# MDR32F02_rev1 register map
File version: 2.0
MDR32F02. Rev. 1.x
CPU: BM-310S, little endian
Registers are 32-bit, read-write, no defined reset value unless marked. A register's access mark holds for its fields unless they carry their own. Offsets are from the block's base; lines under a group give offsets from that group; [hi:lo] are bit positions; {n}, {i} and the like mark numbered series; 'fields as' and 'values as' point back to an identical list; <NAME> marks a mode.

## Memory map
0x02000000 CLINT blocks up to offset 0xC000 — Core Local Interrupt Controller
0x0C000000 PLIC blocks up to offset 0x200008 — Platform Level Interrupt Controller
0x40000000 SSP1 size 0x1000 — SSP1 Interface
0x40008000 UART1 size 0x1000 — UART1 Controller
0x40010000 UART2 size 0x1000 — UART2 Controller
0x40018000 FLASH_CNTRL size 0x1000 — FLASH Memory Controller
0x40020000 RST_CLK size 0x1000 — RST_CLK description
0x40028000 DMA size 0x1000 — DMA description
0x40030000 I2C size 0x1000 — I2C description
0x40038000 UART3 size 0x1000 — UART3 Controller
0x40040000 ADC size 0x1000 — ADC description
0x40048000 WWDG size 0x1000 — WWDG description
0x40050000 IWDG size 0x1000 — IWDG description
0x40058000 POWER size 0x1000 — POWER description
0x40060000 BKP size 0x1000 — BKP description
0x40068000 ADCUI size 0x1000 — ADCUI description
0x40070000 TIMER1 size 0x1000 — TIMER1 description
0x40078000 TIMER2 size 0x1000 — TIMER2 description
0x40080000 PORTA size 0x1000 — PORTA description
0x40088000 PORTB size 0x1000 — PORTB description
0x40090000 PORTC size 0x1000 — PORTC description
0x40098000 CRC size 0x1000 — CRC description
0x400A8000 SENSORS size 0x1000 — SENSORS description
0x400B0000 CLK_MEASURE size 0x1000 — CLK_MEASURE description
0x400B8000 RANDOM size 0x1000 — RANDOM description
0x400C0000 USART size 0x1000 — USART description
0x400C8000 SSP2 size 0x1000 — SSP2 Interface
0x400D0000 SSP3 size 0x1000 — SSP3 Interface
0x400D8000 TIMER3 size 0x1000 — TIMER3 description
0x400E0000 TIMER4 size 0x1000 — TIMER4 description
0x400E8000 UART4 size 0x1000 — UART4 Controller
0x400F0000 PORTD size 0x1000 — PORTD description
0x60004000 L_BLOCK size 0x1000 — L_BLOCK description
{0x60008000+0x4000*n} S_BLOCK{n} size 0x1000 (n=0..7) — S_BLOCK{n} description
0x60028000 P_BYTE size 0x1000 — P_BYTE description
0x6002C000 P_BIT0 size 0x1000 — P_BIT0 description
0x60030000 P_BIT1 size 0x1000 — P_BIT1 description
0x60034000 P_BIT2 size 0x1000 — P_BIT2 description
0x60038000 P_BIT3 size 0x1000 — P_BIT3 description
0x70010000 OTP size 0x1000 — OTP description

## Interrupts
0 DMA_IRQ (DMA)
1 UART1_IRQ (UART1)
2 UART2_IRQ (UART2)
3 SSP1_IRQ (SSP1)
4 POWER_IRQ (POWER)
5 WWDG_IRQ (WWDG)
6 TIMER1_IRQ (TIMER1)
7 TIMER2_IRQ (TIMER2)
8 ADC_IRQ (ADC)
9 I2C_IRQ (I2C)
10 BKP_IRQ (BKP)
11 EXT_INT1_IRQ (PORTA)
12 EXT_INT2_IRQ (PORTB)
13 EXT_INT3_IRQ (PORTC)
14 ADCUI_F03_IRQn (ADCUI)
15 ADCUI_F1_IRQn (ADCUI)
16 ADCUI_F2_IRQn (ADCUI)
17 L_BLOCK_IRQ (L_BLOCK)
19 SENSORS_IRQ (SENSORS)
20 CLK_MEASURE_IRQ (CLK_MEASURE)
21 RANDOM_IRQ (RANDOM)
22 USART_IRQ (USART)
23 UART3_IRQ (UART3)
24 SSP2_IRQ (SSP2)
25 SSP3_IRQ (SSP3)
26 TIMER3_IRQ (TIMER3)
27 TIMER4_IRQ (TIMER4)
28 UART4_IRQ (UART4)
29 OTP_IRQ (OTP)

## CLINT — Core Local Interrupt Controller
Base 0x02000000
0x00 CTMSIP — Software Interrupt Request/Clear Register
0x4000 CTMTIMECMP 64-bit — Machine Timer Compare Register
0xBFF8 CTMTIME 64-bit — Machine Timer Value Register

## PLIC — Platform Level Interrupt Controller
Base 0x0C000000
0x04 PRI1 — 1st Interrupt Priority Register
  [2:0] PRI — Interrupt Priority
0x08 PRI2 — 2nd Interrupt Priority Register
  [2:0] PRI — Interrupt Priority
0x0C PRI3 — 3rd Interrupt Priority Register
  [2:0] PRI — Interrupt Priority
{0x0+4i} PRI{i} (i=4..20) — {i}th Interrupt Priority Register
  [2:0] PRI — Interrupt Priority
0x54 PRI21 — 21st Interrupt Priority Register
  [2:0] PRI — Interrupt Priority
0x58 PRI22 — 22nd Interrupt Priority Register
  [2:0] PRI — Interrupt Priority
0x5C PRI23 — 23rd Interrupt Priority Register
  [2:0] PRI — Interrupt Priority
{0x0+4i} PRI{i} (i=24..30) — {i}th Interrupt Priority Register
  [2:0] PRI — Interrupt Priority
0x7C PRI31 — 31st Interrupt Priority Register
  [2:0] PRI — Interrupt Priority
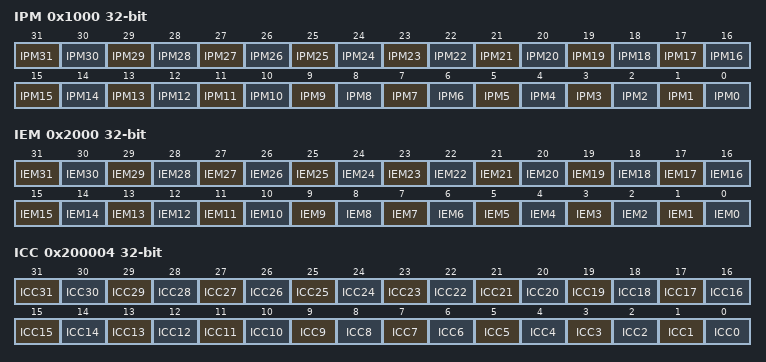
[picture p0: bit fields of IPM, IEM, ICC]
0x1000 IPM ro — Interrupt Presence Mask Register
  [31] IPM31 — 31st Interrupt Pending
  [n] IPM{n} (n=24..30) — {n}th Interrupt Pending
  [23] IPM23 — 23rd Interrupt Pending
  [22] IPM22 — 22nd Interrupt Pending
  [21] IPM21 — 21st Interrupt Pending
  [n] IPM{n} (n=4..20) — {n}th Interrupt Pending
  [3] IPM3 — 3rd Interrupt Pending
  [2] IPM2 — 2nd Interrupt Pending
  [1] IPM1 — 1st Interrupt Pending
  [0] IPM0 — IPM0, always 0
0x2000 IEM — Interrupt Enable Mask Register
  [31] IEM31 — 31st Interrupt Enable Mask
  [n] IEM{n} (n=24..30) — {n}th Interrupt Enable Mask
  [23] IEM23 — 23rd Interrupt Enable Mask
  [22] IEM22 — 22nd Interrupt Enable Mask
  [21] IEM21 — 21st Interrupt Enable Mask
  [n] IEM{n} (n=4..20) — {n}th Interrupt Enable Mask
  [3] IEM3 — 3rd Interrupt Enable Mask
  [2] IEM2 — 2nd Interrupt Enable Mask
  [1] IEM1 — 1st Interrupt Enable Mask
  [0] IEM0 — IEM0, always 0
0x200000 THR — Interrupt Priority Threshold Register
  [2:0] THR — Threshold level
0x200004 ICC — Interrupt Claiming/Completion Register
  [31] ICC31 — 31st Interrupt Claiming/Completion
  [n] ICC{n} (n=24..30) — {n}th Interrupt Claiming/Completion
  [23] ICC23 — 23rd Interrupt Claiming/Completion
  [22] ICC22 — 22nd Interrupt Claiming/Completion
  [21] ICC21 — 21st Interrupt Claiming/Completion
  [n] ICC{n} (n=4..20) — {n}th Interrupt Claiming/Completion
  [3] ICC3 — 3rd Interrupt Claiming/Completion
  [2] ICC2 — 2nd Interrupt Claiming/Completion
  [1] ICC1 — 1st Interrupt Claiming/Completion
  [0] ICC0 — ICC0, always 0
